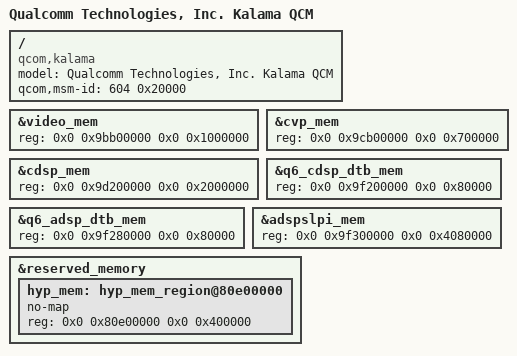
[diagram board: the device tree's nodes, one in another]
#include "kalama-v2.dtsi"

/ {
	model = "Qualcomm Technologies, Inc. Kalama QCM";
	compatible = "qcom,kalama";
	qcom,msm-id = <604 0x20000>;
};

&video_mem {
	reg = <0x0 0x9bb00000 0x0 0x1000000>;
};

&cvp_mem {
	reg = <0x0 0x9cb00000 0x0 0x700000>;
};

&cdsp_mem {
	reg = <0x0 0x9d200000 0x0 0x2000000>;
};

&q6_cdsp_dtb_mem {
	reg = <0x0 0x9f200000 0x0 0x80000>;
};

&q6_adsp_dtb_mem {
	reg = <0x0 0x9f280000 0x0 0x80000>;
};

&adspslpi_mem {
	reg = <0x0 0x9f300000 0x0 0x4080000>;
};

&reserved_memory {
	hyp_mem: hyp_mem_region@80e00000 {
		no-map;
		reg = <0x0 0x80e00000 0x0 0x400000>;
	};
};
